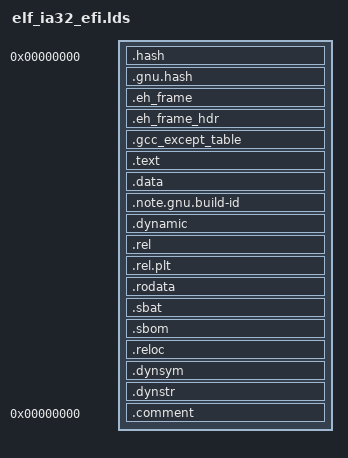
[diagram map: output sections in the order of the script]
OUTPUT_FORMAT("elf32-i386", "elf32-i386", "elf32-i386")
OUTPUT_ARCH(i386)
ENTRY(_start)
SECTIONS
{
  . = 0;
  ImageBase = .;
  /* .hash and/or .gnu.hash MUST come first! */
  .hash : { *(.hash) }
  .gnu.hash : { *(.gnu.hash) }
  .eh_frame : { *(.eh_frame) }
  .eh_frame_hdr : { *(.eh_frame_hdr) }
  .gcc_except_table : { *(.gcc_except_table*) }
  . = ALIGN(4096);
  .text :
  {
    *(.text.head)
   _text = .;
   *(.text)
   *(.text.*)
   *(.gnu.linkonce.t.*)
   *(.plt)
   . = ALIGN(16);
    _evtext = .;
    . = ALIGN(4096);
    _etext = .;
  } =0
  _text_vsize = _evtext - _text;
  _text_size = _etext - _text;
  . = ALIGN(4096);
  .data :
  {
   _data = .;
   *(.got.plt)
   *(.got)
   *(.data)
   *(.data1)
   *(.data.*)

   /*
    * Note that these aren't the using the GNU "CONSTRUCTOR" output section
    * command, so they don't start with a size.  Because of p2align and the
    * end/END definitions, and the fact that they're mergeable, they can also
    * have NULLs which aren't guaranteed to be at the end.
    */
   . = ALIGN(16);
   __init_array_start = .;
   *(SORT(.init_array.*))
   *(.init_array)
   __init_array_end = .;
  . = ALIGN(16);
   __CTOR_LIST__ = .;
   *(SORT(.ctors.*))
   *(.ctors)
   __CTOR_END__ = .;
  . = ALIGN(16);
   __DTOR_LIST__ = .;
   *(SORT(.dtors.*))
   *(.dtors)
   __DTOR_END__ = .;
   . = ALIGN(16);
   __fini_array_start = .;
   *(SORT(.fini_array.*))
   *(.fini_array)
   __fini_array_end = .;

   /* the EFI loader doesn't seem to like a .bss section, so we stick
      it all into .data: */
   _bss = .;
   *(.dynbss)
   *(.bss*)
   *(COMMON)
   _bss_end = .;
   _evdata = .;
   . = ALIGN(4096);
   _edata = .;
  } =0
  _data_vsize = _evdata - _data;
  _data_size = _edata - _data;
  .note.gnu.build-id : { *(.note.gnu.build-id) }

  . = ALIGN(4096);
  .dynamic  : { *(.dynamic) }
  . = ALIGN(4096);
  _rodata = .;
  .rel :
  {
    *(.rel.text*)
    *(.rel.data*)
    *(.rel.got)
    *(.rel.dyn)
    *(.rel.stab)
    *(.rel.init_array*)
    *(.rel.fini_array*)
    *(.rel.ctors*)
    *(.rel.dtors*)
    *(.data.rel.ro.local)
    *(.data.rel.local)
    *(.data.rel.ro)
    *(.data.rel*)
  }
  . = ALIGN(4096);
  .rel.plt : { *(.rel.plt) }
  . = ALIGN(4096);
  .rodata : {
    *(.rodata*)
    _evrodata = .;
    . = ALIGN(4096);
    _erodata = .;
  } =0
  _rodata_vsize = _evrodata - _rodata;
  _rodata_size = _erodata - _rodata;
  /*
   * Note that _sbat must be the beginning of the data, and _esbat must be the
   * end and must be before any section padding.  The sbat self-check uses
   * _esbat to find the bounds of the data, and if the padding is included, the
   * CSV parser (correctly) rejects the data as having NUL values in one of the
   * required columns.
   */
  . = ALIGN(4096);
  .sbat :
  {
    _sbat = .;
    *(.sbat)
    *(.sbat.*)
    _esbat = .;
    . = ALIGN(4096);
    _epsbat = .;
  } =0
  _sbat_size = _epsbat - _sbat;
  _sbat_vsize = _esbat - _sbat;
  _edata = .;
  _data_size = _edata - _etext;
  . = ALIGN(4096);
  .sbom :
  {
    _sbom = .;
    *(.sbom)
    _esbom = .;
    . = ALIGN(4096);
    _epsbom = .;
  } =0
  _sbom_size = _epsbom - _sbom;
  _sbom_vsize = _esbom - _sbom;
  . = ALIGN(4096);
  _reloc = .;
  .reloc :		/* This is the PECOFF .reloc section! */
  {
    KEEP (*(.reloc))
    _evreloc = .;
    . = ALIGN(4096);
    _ereloc = .;
  } =0
  _reloc_vsize = _evreloc - _reloc;
  _reloc_size = _ereloc - _reloc;

  _image_end = .;
  _alldata_size = _image_end - _reloc;

  . = ALIGN(4096);
  .dynsym   : { *(.dynsym) }
  . = ALIGN(4096);
  .dynstr   : { *(.dynstr) }
  /DISCARD/ :
  {
    *(.rel.reloc)
    *(.note.GNU-stack)
  }
  .comment 0 : { *(.comment) }
}
